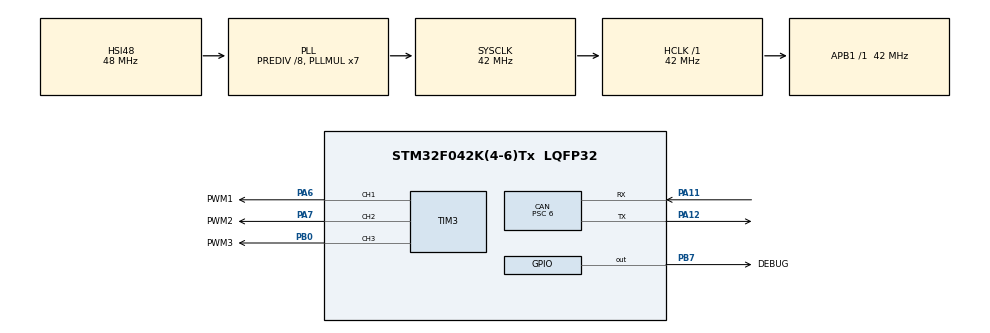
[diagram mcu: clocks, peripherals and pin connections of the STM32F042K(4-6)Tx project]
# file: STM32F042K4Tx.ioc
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CAN.ABOM=DISABLE
CAN.AWUM=DISABLE
CAN.BS1=CAN_BS1_11TQ
CAN.BS2=CAN_BS2_2TQ
CAN.CalculateBaudRate=500000
CAN.CalculateTimeBit=2000
CAN.CalculateTimeQuantum=142.85714285714286
CAN.NART=ENABLE
CAN.Prescaler=6
Mcu.Family=STM32F0
Mcu.Name=STM32F042K(4-6)Tx
Mcu.Package=LQFP32
NVIC.CEC_CAN_IRQn=true\:0\:0\:false\:false\:true\:true\:true
NVIC.TIM14_IRQn=true\:0\:0\:false\:false\:true\:true\:true
NVIC.TIM16_IRQn=true\:0\:0\:false\:false\:true\:true\:true
PA11.Mode=CAN_Activate
PA11.Signal=CAN_RX
PA12.Mode=CAN_Activate
PA12.Signal=CAN_TX
PA13.Mode=Serial_Wire
PA13.Signal=SYS_SWDIO
PA14.Mode=Serial_Wire
PA14.Signal=SYS_SWCLK
PA6.GPIO_Label=PWM1
PA6.Signal=S_TIM3_CH1
PA7.GPIO_Label=PWM2
PA7.Signal=S_TIM3_CH2
PB0.GPIO_Label=PWM3
PB0.Signal=S_TIM3_CH3
PB7.GPIO_Label=DEBUG
PB7.Signal=GPIO_Output
PF0-OSC_IN.Mode=HSE-External-Oscillator
PF0-OSC_IN.Signal=RCC_OSC_IN
PF1-OSC_OUT.Mode=HSE-External-Oscillator
PF1-OSC_OUT.Signal=RCC_OSC_OUT
ProjectManager.HeapSize=0x200
ProjectManager.StackSize=0x400
ProjectManager.TargetToolchain=STM32CubeIDE
RCC.AHBFreq_Value=42000000
RCC.APB1Freq_Value=42000000
RCC.APB1TimFreq_Value=42000000
RCC.HCLKFreq_Value=42000000
RCC.PLLDivider=RCC_PREDIV_DIV8
RCC.PLLMUL=RCC_PLL_MUL7
RCC.PLLSourceVirtual=RCC_PLLSOURCE_HSI48
RCC.SYSCLKFreq_VALUE=42000000
RCC.SYSCLKSource=RCC_SYSCLKSOURCE_PLLCLK
SH.S_TIM3_CH1.0=TIM3_CH1,PWM Generation1 CH1
SH.S_TIM3_CH2.0=TIM3_CH2,PWM Generation2 CH2
SH.S_TIM3_CH3.0=TIM3_CH3,PWM Generation3 CH3
TIM14.AutoReloadPreload=TIM_AUTORELOAD_PRELOAD_ENABLE
TIM14.Period=41999
TIM14.Prescaler=199
TIM16.AutoReloadPreload=TIM_AUTORELOAD_PRELOAD_ENABLE
TIM16.Period=9999
TIM16.Prescaler=2099
TIM3.AutoReloadPreload=TIM_AUTORELOAD_PRELOAD_ENABLE
TIM3.Channel-PWM\ Generation1\ CH1=TIM_CHANNEL_1
TIM3.Channel-PWM\ Generation2\ CH2=TIM_CHANNEL_2
TIM3.Channel-PWM\ Generation3\ CH3=TIM_CHANNEL_3
VP_TIM14_VS_ClockSourceINT.Mode=Enable_Timer
VP_TIM16_VS_ClockSourceINT.Mode=Enable_Timer
board=custom

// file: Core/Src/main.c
/* USER CODE BEGIN Header */
/**
  ******************************************************************************
  * @file           : main.c
  * @brief          : Main program body
  ******************************************************************************
  * @attention
  *
  * Copyright (c) 2022 STMicroelectronics.
  * All rights reserved.
  *
  * This software is licensed under terms that can be found in the LICENSE file
  * in the root directory of this software component.
  * If no LICENSE file comes with this software, it is provided AS-IS.
  *
  ******************************************************************************
  */
/* USER CODE END Header */
#include "main.h"

/* USER CODE BEGIN Includes */
#include "state_machine_utils.h"

/* USER CODE END Includes */

CAN_HandleTypeDef hcan;

TIM_HandleTypeDef htim3;
TIM_HandleTypeDef htim14;
TIM_HandleTypeDef htim16;

void SystemClock_Config(void);
static void MX_GPIO_Init(void);
static void MX_CAN_Init(void);
static void MX_TIM3_Init(void);
static void MX_TIM14_Init(void);
static void MX_TIM16_Init(void);

int main(void)
{

  /* MCU Configuration--------------------------------------------------------*/

  /* Reset of all peripherals, Initializes the Flash interface and the Systick. */
  HAL_Init();

  /* Configure the system clock */
  SystemClock_Config();

  /* Initialize all configured peripherals */
  MX_GPIO_Init();
  MX_CAN_Init();
  MX_TIM3_Init();
  MX_TIM14_Init();
  MX_TIM16_Init();
  /* USER CODE BEGIN 2 */

  // start_timers();
  // init_can();
  // StateID state = RESTING;

  // Call main PIL routine
  return pilMain();

  /* USER CODE END 2 */

  /* Infinite loop */
  while (1)
  {

  }
}

void SystemClock_Config(void)
{
  RCC_OscInitTypeDef RCC_OscInitStruct = {0};
  RCC_ClkInitTypeDef RCC_ClkInitStruct = {0};

  /** Initializes the RCC Oscillators according to the specified parameters
  * in the RCC_OscInitTypeDef structure.
  */
  RCC_OscInitStruct.OscillatorType = RCC_OSCILLATORTYPE_HSI48;
  RCC_OscInitStruct.HSI48State = RCC_HSI48_ON;
  RCC_OscInitStruct.PLL.PLLState = RCC_PLL_ON;
  RCC_OscInitStruct.PLL.PLLSource = RCC_PLLSOURCE_HSI48;
  RCC_OscInitStruct.PLL.PLLMUL = RCC_PLL_MUL7;
  RCC_OscInitStruct.PLL.PREDIV = RCC_PREDIV_DIV8;
  if (HAL_RCC_OscConfig(&RCC_OscInitStruct) != HAL_OK)
  {
    Error_Handler();
  }
  /** Initializes the CPU, AHB and APB buses clocks
  */
  RCC_ClkInitStruct.ClockType = RCC_CLOCKTYPE_HCLK|RCC_CLOCKTYPE_SYSCLK
                              |RCC_CLOCKTYPE_PCLK1;
  RCC_ClkInitStruct.SYSCLKSource = RCC_SYSCLKSOURCE_PLLCLK;
  RCC_ClkInitStruct.AHBCLKDivider = RCC_SYSCLK_DIV1;
  RCC_ClkInitStruct.APB1CLKDivider = RCC_HCLK_DIV1;

  if (HAL_RCC_ClockConfig(&RCC_ClkInitStruct, FLASH_LATENCY_1) != HAL_OK)
  {
    Error_Handler();
  }
}

static void MX_CAN_Init(void)
{

  hcan.Instance = CAN;
  hcan.Init.Prescaler = 6;
  hcan.Init.Mode = CAN_MODE_NORMAL;
  hcan.Init.SyncJumpWidth = CAN_SJW_1TQ;
  hcan.Init.TimeSeg1 = CAN_BS1_11TQ;
  hcan.Init.TimeSeg2 = CAN_BS2_2TQ;
  hcan.Init.TimeTriggeredMode = DISABLE;
  hcan.Init.AutoBusOff = DISABLE;
  hcan.Init.AutoWakeUp = DISABLE;
  hcan.Init.AutoRetransmission = ENABLE;
  hcan.Init.ReceiveFifoLocked = DISABLE;
  hcan.Init.TransmitFifoPriority = DISABLE;
  if (HAL_CAN_Init(&hcan) != HAL_OK)
  {
    Error_Handler();
  }

}

static void MX_TIM3_Init(void)
{

  TIM_MasterConfigTypeDef sMasterConfig = {0};
  TIM_OC_InitTypeDef sConfigOC = {0};

  htim3.Instance = TIM3;
  htim3.Init.Prescaler = 0;
  htim3.Init.CounterMode = TIM_COUNTERMODE_UP;
  htim3.Init.Period = 65535;
  htim3.Init.ClockDivision = TIM_CLOCKDIVISION_DIV1;
  htim3.Init.AutoReloadPreload = TIM_AUTORELOAD_PRELOAD_ENABLE;
  if (HAL_TIM_PWM_Init(&htim3) != HAL_OK)
  {
    Error_Handler();
  }
  sMasterConfig.MasterOutputTrigger = TIM_TRGO_RESET;
  sMasterConfig.MasterSlaveMode = TIM_MASTERSLAVEMODE_DISABLE;
  if (HAL_TIMEx_MasterConfigSynchronization(&htim3, &sMasterConfig) != HAL_OK)
  {
    Error_Handler();
  }
  sConfigOC.OCMode = TIM_OCMODE_PWM1;
  sConfigOC.Pulse = 0;
  sConfigOC.OCPolarity = TIM_OCPOLARITY_HIGH;
  sConfigOC.OCFastMode = TIM_OCFAST_DISABLE;
  if (HAL_TIM_PWM_ConfigChannel(&htim3, &sConfigOC, TIM_CHANNEL_1) != HAL_OK)
  {
    Error_Handler();
  }
  if (HAL_TIM_PWM_ConfigChannel(&htim3, &sConfigOC, TIM_CHANNEL_2) != HAL_OK)
  {
    Error_Handler();
  }
  if (HAL_TIM_PWM_ConfigChannel(&htim3, &sConfigOC, TIM_CHANNEL_3) != HAL_OK)
  {
    Error_Handler();
  }
  HAL_TIM_MspPostInit(&htim3);

}

static void MX_TIM14_Init(void)
{

  htim14.Instance = TIM14;
  htim14.Init.Prescaler = 199;
  htim14.Init.CounterMode = TIM_COUNTERMODE_UP;
  htim14.Init.Period = 41999;
  htim14.Init.ClockDivision = TIM_CLOCKDIVISION_DIV1;
  htim14.Init.AutoReloadPreload = TIM_AUTORELOAD_PRELOAD_ENABLE;
  if (HAL_TIM_Base_Init(&htim14) != HAL_OK)
  {
    Error_Handler();
  }

}

static void MX_TIM16_Init(void)
{

  htim16.Instance = TIM16;
  htim16.Init.Prescaler = 2099;
  htim16.Init.CounterMode = TIM_COUNTERMODE_UP;
  htim16.Init.Period = 9999;
  htim16.Init.ClockDivision = TIM_CLOCKDIVISION_DIV1;
  htim16.Init.RepetitionCounter = 0;
  htim16.Init.AutoReloadPreload = TIM_AUTORELOAD_PRELOAD_ENABLE;
  if (HAL_TIM_Base_Init(&htim16) != HAL_OK)
  {
    Error_Handler();
  }

}

static void MX_GPIO_Init(void)
{
  GPIO_InitTypeDef GPIO_InitStruct = {0};

  /* GPIO Ports Clock Enable */
  __HAL_RCC_GPIOF_CLK_ENABLE();
  __HAL_RCC_GPIOA_CLK_ENABLE();
  __HAL_RCC_GPIOB_CLK_ENABLE();

  /*Configure GPIO pin Output Level */
  HAL_GPIO_WritePin(DEBUG_GPIO_Port, DEBUG_Pin, GPIO_PIN_RESET);

  /*Configure GPIO pin : DEBUG_Pin */
  GPIO_InitStruct.Pin = DEBUG_Pin;
  GPIO_InitStruct.Mode = GPIO_MODE_OUTPUT_PP;
  GPIO_InitStruct.Pull = GPIO_NOPULL;
  GPIO_InitStruct.Speed = GPIO_SPEED_FREQ_LOW;
  HAL_GPIO_Init(DEBUG_GPIO_Port, &GPIO_InitStruct);

}

void Error_Handler(void)
{
  __disable_irq();
  while (1)
  {
  }
}
